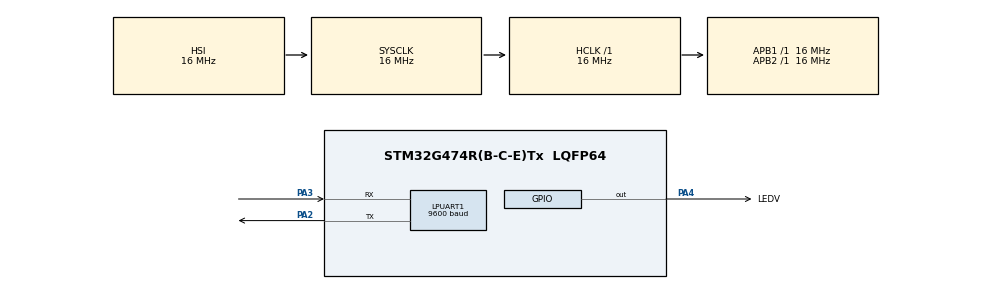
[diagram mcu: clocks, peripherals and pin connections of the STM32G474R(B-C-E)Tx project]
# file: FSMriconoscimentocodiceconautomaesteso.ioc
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LPUART1.BaudRate=9600
Mcu.Family=STM32G4
Mcu.Name=STM32G474R(B-C-E)Tx
Mcu.Package=LQFP64
NVIC.LPUART1_IRQn=true\:0\:0\:false\:false\:true\:true\:true\:true
NVIC.PriorityGroup=NVIC_PRIORITYGROUP_4
PA2.Mode=Asynchronous
PA2.Signal=LPUART1_TX
PA3.Mode=Asynchronous
PA3.Signal=LPUART1_RX
PA4.GPIO_Label=LEDV
PA4.Signal=GPIO_Output
ProjectManager.HeapSize=0x200
ProjectManager.StackSize=0x400
ProjectManager.TargetToolchain=STM32CubeIDE
RCC.AHBFreq_Value=16000000
RCC.APB1Freq_Value=16000000
RCC.APB1TimFreq_Value=16000000
RCC.APB2Freq_Value=16000000
RCC.APB2TimFreq_Value=16000000
RCC.CortexFreq_Value=16000000
RCC.EXTERNAL_CLOCK_VALUE=12288000
RCC.HCLKFreq_Value=16000000
RCC.HSE_VALUE=8000000
RCC.HSI48_VALUE=48000000
RCC.HSI_VALUE=16000000
RCC.LSE_VALUE=32768
RCC.SYSCLKFreq_VALUE=16000000
RCC.USBFreq_Value=64000000
RCC.VCOOutputFreq_Value=128000000
VP_SYS_VS_DBSignals.Mode=DisableDeadBatterySignals
board=custom

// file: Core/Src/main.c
/* USER CODE BEGIN Header */
/**
  ******************************************************************************
  * @file           : main.c
  * @brief          : Main program body
  ******************************************************************************
  * @attention
  *
  * Copyright (c) 2026 STMicroelectronics.
  * All rights reserved.
  *
  * This software is licensed under terms that can be found in the LICENSE file
  * in the root directory of this software component.
  * If no LICENSE file comes with this software, it is provided AS-IS.
  *
  ******************************************************************************
  */
/* USER CODE END Header */
#include "main.h"
#include "usart.h"
#include "gpio.h"

/* USER CODE BEGIN Includes */
#include "fsm_logic.h"
/* USER CODE END Includes */

/* USER CODE BEGIN PV */
led_t led_verde;
/* USER CODE END PV */

void SystemClock_Config(void);

int main(void)
{

  /* MCU Configuration--------------------------------------------------------*/

  /* Reset of all peripherals, Initializes the Flash interface and the Systick. */
  HAL_Init();

  /* Configure the system clock */
  SystemClock_Config();

  /* Initialize all configured peripherals */
  MX_GPIO_Init();
  MX_LPUART1_UART_Init();
  /* USER CODE BEGIN 2 */
  if(led_init(&led_verde, GPIOA, LEDV_Pin, GPIO_PIN_RESET)!= LED_OK){
    return -1;
  }
  if(FSM_init(&led_verde, FSM_CYCLE_DURATION) != FSM_OK){
    return -1;
  }

  /* USER CODE END 2 */

  /* Infinite loop */
  while (1)
  {
    if(FSM_step() != FSM_OK){
      return -1;
    }

  }
}

void SystemClock_Config(void)
{
  RCC_OscInitTypeDef RCC_OscInitStruct = {0};
  RCC_ClkInitTypeDef RCC_ClkInitStruct = {0};

  /** Configure the main internal regulator output voltage
  */
  HAL_PWREx_ControlVoltageScaling(PWR_REGULATOR_VOLTAGE_SCALE1);

  /** Initializes the RCC Oscillators according to the specified parameters
  * in the RCC_OscInitTypeDef structure.
  */
  RCC_OscInitStruct.OscillatorType = RCC_OSCILLATORTYPE_HSI;
  RCC_OscInitStruct.HSIState = RCC_HSI_ON;
  RCC_OscInitStruct.HSICalibrationValue = RCC_HSICALIBRATION_DEFAULT;
  RCC_OscInitStruct.PLL.PLLState = RCC_PLL_NONE;
  if (HAL_RCC_OscConfig(&RCC_OscInitStruct) != HAL_OK)
  {
    Error_Handler();
  }

  /** Initializes the CPU, AHB and APB buses clocks
  */
  RCC_ClkInitStruct.ClockType = RCC_CLOCKTYPE_HCLK|RCC_CLOCKTYPE_SYSCLK
                              |RCC_CLOCKTYPE_PCLK1|RCC_CLOCKTYPE_PCLK2;
  RCC_ClkInitStruct.SYSCLKSource = RCC_SYSCLKSOURCE_HSI;
  RCC_ClkInitStruct.AHBCLKDivider = RCC_SYSCLK_DIV1;
  RCC_ClkInitStruct.APB1CLKDivider = RCC_HCLK_DIV1;
  RCC_ClkInitStruct.APB2CLKDivider = RCC_HCLK_DIV1;

  if (HAL_RCC_ClockConfig(&RCC_ClkInitStruct, FLASH_LATENCY_0) != HAL_OK)
  {
    Error_Handler();
  }
}

void Error_Handler(void)
{
  __disable_irq();
  while (1)
  {
  }
}
